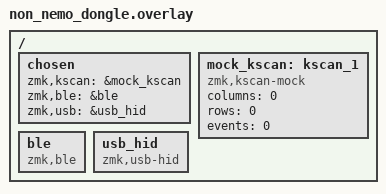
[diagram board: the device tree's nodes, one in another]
#include "non_nemo.dtsi"

/ {
   chosen {
      zmk,kscan = &mock_kscan;
      zmk,ble = &ble;
      zmk,usb = &usb_hid;
   };

   mock_kscan: kscan_1 {
      compatible = "zmk,kscan-mock";
      columns = <0>;
      rows = <0>;
      events = <0>;
   };

   ble: ble {
      compatible = "zmk,ble";
   };

   usb_hid: usb_hid {
      compatible = "zmk,usb-hid";
   };
};
